# ISS_CSI2_A_REGS2 register map
Vendor: Texas Instruments
Peripheral module from a debugger description file (folder omap4430).
Registers are 32-bit, access per field, reset 0x0 unless marked. A register's access mark holds for its fields unless they carry their own. Offsets are as the file gives them; lines under a group give offsets from that group; [hi:lo] are bit positions; {n}, {i} and the like mark numbered series; 'fields as' and 'values as' point back to an identical list; <NAME> marks a mode.

## ISS_CSI2_A_REGS2
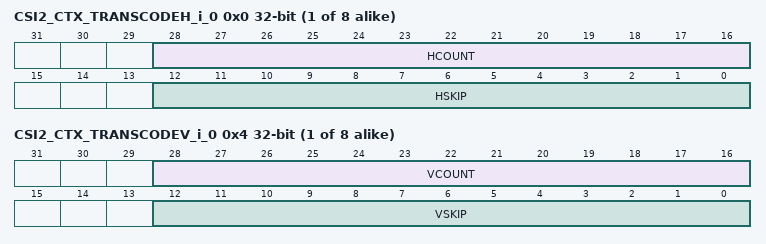
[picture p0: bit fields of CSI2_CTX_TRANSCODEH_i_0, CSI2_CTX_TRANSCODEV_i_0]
{0x0+8i} CSI2_CTX_TRANSCODEH_i_{i} (i=0..7) — Transcode configuration register: defines horizontal frame cropping
  [28:16] HCOUNT rw — Pixels to output per line when the values is between 1 and 8191. Pixels HSKIP-WIDTH pixels are output when HCOUNT=0. WIDTH corresponds to the image width provided by the sensor.
  [12:0] HSKIP rw — Pixel to skip horizontally. Valid values: 0-8191
{0x4+8i} CSI2_CTX_TRANSCODEV_i_{i} (i=0..7) — Transcode configuration register: defines vertical frame cropping
  [28:16] VCOUNT rw — Lines to output per frame when the values is between 1 and 8191. Pixels VSKIP-HEIGHT pixels are output when VCOUNT=0. HEIGHT corresponds to the image height provided by the sensor.
  [12:0] VSKIP rw — Pixel to skip vertically Valid values: 0-8191
